AUTOSAR XML (schema 4-0-3)
standard types defined: boolean, float32, float64, sint16, sint32, sint8, uint16, uint32, uint8
package /ApplDataTypes
  5 x app type, all with category=VALUE:
    ActionRequest
    ButtonState
    LedState
    LockState
    WindowPosition
package /ImplDataTypes
  5 x impl type, all with category=VALUE:
    ActionRequest: base-type=boolean
    ButtonState: base-type=boolean
    LedState: base-type=boolean
    LockState: base-type=boolean
    WindowPosition: base-type=uint8
package /Interfaces
  sender receiver interface IfActionRequest
    data up: type=ActionRequest
    data down: type=ActionRequest
  4 x client server interface:
    IfButtonState
      operation GetButtonState
        arg up: type=ButtonState, direction=OUT
        arg down: type=ButtonState, direction=OUT
    IfLedState
      operation SetLedState
        arg state: type=LedState, direction=IN
    IfLockState
      operation GetLockState
        arg state: type=LockState, direction=OUT
    IfWindowPosition
      operation SetWindowPosition
        arg position: type=WindowPosition, direction=IN
package /PowerWindowController
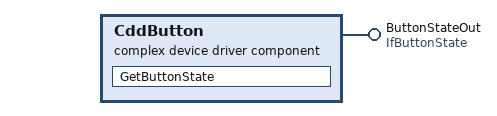
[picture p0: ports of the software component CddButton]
  complex device driver sw component type CddButton
    provide port ButtonStateOut: provided-interface=IfButtonState
    behavior IB_CB: data-type-mapping=PWC_DTM, handle-termination-and-restart=NO-SUPPORT
      operation invoked event OperationInvokedEvent: start-on-event=GetButtonState, operation=ButtonStateOut.GetButtonState
      runnable GetButtonState
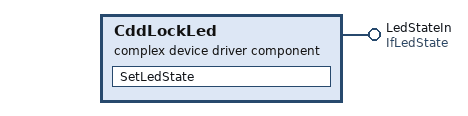
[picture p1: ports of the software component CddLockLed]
  complex device driver sw component type CddLockLed
    provide port LedStateIn: provided-interface=IfLedState
    behavior IB_CLL: data-type-mapping=PWC_DTM, handle-termination-and-restart=NO-SUPPORT
      operation invoked event OperationInvokedEvent: start-on-event=SetLedState, operation=LedStateIn.SetLedState
      runnable SetLedState
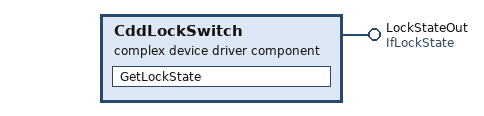
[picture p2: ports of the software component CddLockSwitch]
  complex device driver sw component type CddLockSwitch
    provide port LockStateOut: provided-interface=IfLockState
    behavior IB_CLS: data-type-mapping=PWC_DTM, handle-termination-and-restart=NO-SUPPORT
      operation invoked event OperationInvokedEvent: start-on-event=GetLockState, operation=LockStateOut.GetLockState
      runnable GetLockState
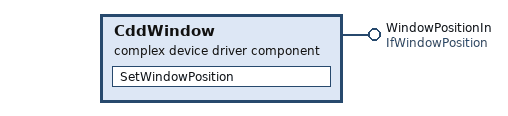
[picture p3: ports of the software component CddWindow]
  complex device driver sw component type CddWindow
    provide port WindowPositionIn: provided-interface=IfWindowPosition
    behavior IB_CW: data-type-mapping=PWC_DTM, handle-termination-and-restart=NO-SUPPORT
      operation invoked event OperationInvokedEvent: start-on-event=SetWindowPosition, operation=WindowPositionIn.SetWindowPosition
      runnable SetWindowPosition
  composition sw component type PWCTopLevel
    6 x component:
      CddButton: type=CddButton
      CddWindow: type=CddWindow
      PowerWindowController: type=PowerWindowController
      SensorButton: type=SensorButton
      CddLockLed: type=CddLockLed
      CddLockSwitch: type=CddLockSwitch
    connect CddButton.ButtonStateOut -> SensorButton.ButtonStateIn
    connect SensorButton.ActionRequestOut -> PowerWindowController.ActionRequestIn
    connect CddWindow.WindowPositionIn -> PowerWindowController.WindowPositionOut
    connect CddLockLed.LedStateIn -> SensorButton.LedStateOut
    connect CddLockSwitch.LockStateOut -> SensorButton.LockStateIn
  data type mapping set PWC_DTM
    data-type-maps:
      application-data-type=ActionRequest, implementation-data-type=ActionRequest
      application-data-type=ButtonState, implementation-data-type=ButtonState
      application-data-type=WindowPosition, implementation-data-type=WindowPosition
      application-data-type=LedState, implementation-data-type=LedState
      application-data-type=LockState, implementation-data-type=LockState
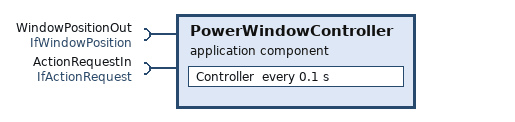
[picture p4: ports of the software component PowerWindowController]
  application sw component type PowerWindowController
    require port WindowPositionOut: required-interface=IfWindowPosition
    require port ActionRequestIn: required-interface=IfActionRequest
    behavior IB_PWC: data-type-mapping=PWC_DTM, handle-termination-and-restart=NO-SUPPORT
      timing event TimingEvent: start-on-event=Controller, period=0.1
      runnable Controller
        data-receive-point-by-arguments:
          access VariableAccess: accessed-variable=ActionRequestIn.up
          access VariableAccess1: accessed-variable=ActionRequestIn.down
        sync call SynchronousServerCallPoint: operation=WindowPositionOut.SetWindowPosition, timeout=0
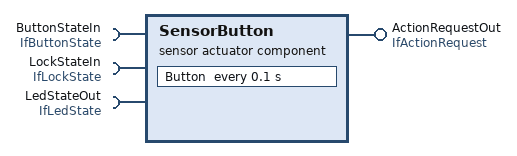
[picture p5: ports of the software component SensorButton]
  sensor actuator sw component type SensorButton: sensor-actuator=CddButton
    provide port ActionRequestOut: provided-interface=IfActionRequest
      provided-com-specs:
        data-element=down, transmission-acknowledge=timeout=0, init-value=TextValue:FALSE
        data-element=up, transmission-acknowledge=timeout=0, init-value=TextValue:FALSE
    require port ButtonStateIn: required-interface=IfButtonState
    require port LockStateIn: required-interface=IfLockState
    require port LedStateOut: required-interface=IfLedState
    behavior IB_SB: data-type-mapping=PWC_DTM, handle-termination-and-restart=NO-SUPPORT
      timing event TimingEvent: start-on-event=Button, period=0.1
      runnable Button
        data-send-points:
          access VariableAccess: accessed-variable=ActionRequestOut.up
          access VariableAccess1: accessed-variable=ActionRequestOut.down
        sync call SynchronousServerCallPoint: operation=ButtonStateIn.GetButtonState, timeout=0
        sync call SynchronousServerCallPoint1: operation=LockStateIn.GetLockState, timeout=0
        sync call SynchronousServerCallPoint2: operation=LedStateOut.SetLedState, timeout=0
package /System
  ecuc value collection EcucValueCollection: ecu-extract=SystemPWC, ecuc-values=[Os, Rte]
  system SystemPWC: system-version=1.0.0
    root-software-compositions:
      root sw composition prototype RootSwCompositionPrototype: software-composition=PWCTopLevel
